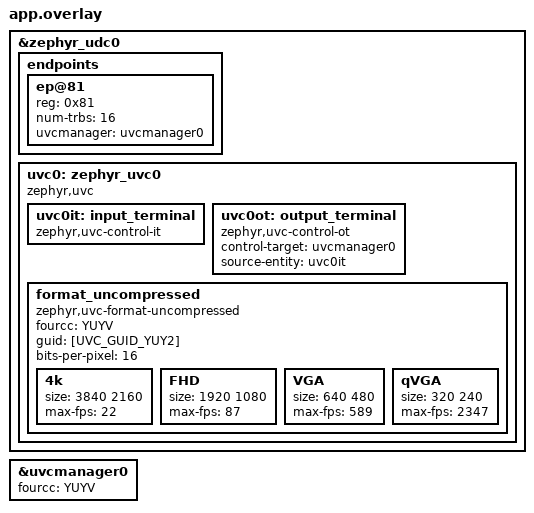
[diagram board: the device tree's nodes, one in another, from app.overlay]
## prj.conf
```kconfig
CONFIG_ASSERT=y

# Shell
CONFIG_SHELL=y
CONFIG_I2C_SHELL=y
CONFIG_KERNEL_SHELL=y
CONFIG_SHELL_BACKEND_SERIAL_CHECK_DTR=y

# Logging
CONFIG_LOG=y
CONFIG_LOG_MODE_MINIMAL=y
CONFIG_UDC_DRIVER_LOG_LEVEL_INF=y
CONFIG_USBD_LOG_LEVEL_INF=y
CONFIG_USBD_UVC_LOG_LEVEL_INF=y
CONFIG_VIDEO_LOG_LEVEL_INF=y

# USB
CONFIG_USBD_VIDEO_CLASS=y
CONFIG_USBD_VIDEO_HEADER_SIZE=8

# Video
CONFIG_VIDEO=y
CONFIG_VIDEO_UVCMANAGER=y
```

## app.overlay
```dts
#include <zephyr/dt-bindings/usb/video.h>

&zephyr_udc0 {
	endpoints {
		/* For USB UVC */
		ep@81 {
			reg = <0x81>;
			num-trbs = <16>;
			uvcmanager = <&uvcmanager0>;
		};
	};

	uvc0: zephyr_uvc0 {
		compatible = "zephyr,uvc";

		uvc0it: input_terminal {
			compatible = "zephyr,uvc-control-it";
		};

		uvc0ot: output_terminal {
			compatible = "zephyr,uvc-control-ot";
			control-target = <&uvcmanager0>;
			source-entity = <&uvc0it>;
		};

		format_uncompressed {
			compatible = "zephyr,uvc-format-uncompressed";
			fourcc = "YUYV";
			guid = [UVC_GUID_YUY2];
			bits-per-pixel = <16>;

			4k {
				size = <3840 2160>;
				max-fps = <22>;
			};

			FHD {
				size = <1920 1080>;
				max-fps = <87>;
			};

			VGA {
				size = <640 480>;
				max-fps = <589>;
			};

			qVGA {
				size = <320 240>;
				max-fps = <2347>;
			};
		};
	};
};

&uvcmanager0 {
	status = "okay";
	fourcc = "YUYV";
};
```

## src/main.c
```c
#include <zephyr/kernel.h>
#include <zephyr/devicetree.h>
#include <zephyr/drivers/video.h>
#include <zephyr/logging/log.h>

LOG_MODULE_REGISTER(app, LOG_LEVEL_DBG);

static const struct device *uvc0_dev = DEVICE_DT_GET(DT_NODELABEL(uvc0));

int main(void)
{
	struct video_buffer vbuf = {0};
	struct video_format fmt = {0};
	int ret;

	/* Get the video format once it is selected by the host */
	while (true) {
		ret = video_get_format(uvc0_dev, VIDEO_EP_IN, &fmt);
		if (ret == 0) {
			break;
		}
		if (ret != -EAGAIN) {
			LOG_ERR("failed to get the video format");
			return ret;
		}

		k_sleep(K_MSEC(10));
	}

	/* The buffer address is the FIFO endpoint */
	vbuf.buffer = (void *)DT_REG_ADDR_BY_NAME(DT_NODELABEL(uvcmanager0), fifo);
	vbuf.size = vbuf.bytesused = fmt.pitch * fmt.height;
	vbuf.flags = VIDEO_BUF_EOF;

	LOG_DBG("frame %ux%u, %u bytes, addr %p", fmt.width, fmt.height, fmt.pitch * fmt.height, vbuf.buffer);

	/* Only the first buffer needs to be enqueued when using the UVC Manager */
	ret = video_enqueue(uvc0_dev, VIDEO_EP_IN, &vbuf);
	if (ret < 0) {
		LOG_ERR("failed to enqueue the video buffer");
		return ret;
	}

	k_sleep(K_FOREVER);
	return 0;
}
```
